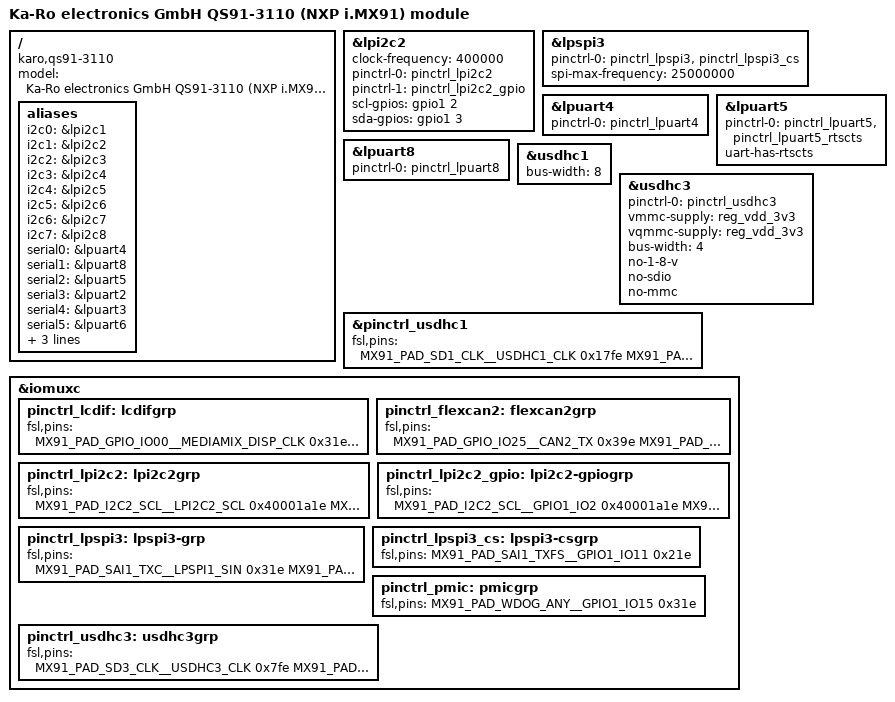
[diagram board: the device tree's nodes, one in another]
// SPDX-License-Identifier: (GPL-2.0+ OR MIT)
/*
 * Copyright 2025 Lothar Waßmann <LW@KARO-electronics.de>
 */

/dts-v1/;

#include "imx91-karo.dtsi"

/ {
	model = "Ka-Ro electronics GmbH QS91-3110 (NXP i.MX91) module";
	compatible = "karo,qs91-3110", "fsl,imx91";

	aliases {
		i2c0 = &lpi2c1; /* PMIC */
		i2c1 = &lpi2c2;
		i2c2 = &lpi2c3;
		i2c3 = &lpi2c4;
		i2c4 = &lpi2c5;
		i2c5 = &lpi2c6;
		i2c6 = &lpi2c7;
		i2c7 = &lpi2c8;
		serial0 = &lpuart4;
		serial1 = &lpuart8;
		serial2 = &lpuart5;
		serial3 = &lpuart2;
		serial4 = &lpuart3;
		serial5 = &lpuart6;
		serial6 = &lpuart7;
		serial7 = &lpuart1;
		mmc1 = &usdhc3;
	};
};

&lpi2c2 {
	clock-frequency = <400000>;
	pinctrl-names = "default", "gpio";
	pinctrl-0 = <&pinctrl_lpi2c2>;
	pinctrl-1 = <&pinctrl_lpi2c2_gpio>;
	scl-gpios = <&gpio1 2 (GPIO_ACTIVE_HIGH | GPIO_OPEN_DRAIN)>;
	sda-gpios = <&gpio1 3 (GPIO_ACTIVE_HIGH | GPIO_OPEN_DRAIN)>;
	status = "okay";
};

&lpspi3 {
	pinctrl-names = "default";
	pinctrl-0 = <&pinctrl_lpspi3 &pinctrl_lpspi3_cs>;
	spi-max-frequency = <25000000>;
};

&lpuart4 { /* console */
	pinctrl-names = "default";
	pinctrl-0 = <&pinctrl_lpuart4>;
	status = "okay";
};

&lpuart5 {
	pinctrl-names = "default";
	pinctrl-0 = <&pinctrl_lpuart5 &pinctrl_lpuart5_rtscts>;
	uart-has-rtscts;
	status = "okay";
};

&lpuart8 {
	pinctrl-names = "default";
	pinctrl-0 = <&pinctrl_lpuart8>;
	status = "okay";
};

&usdhc1 {
	bus-width = <8>;
};

&usdhc3 {
	pinctrl-names = "default";
	pinctrl-0 = <&pinctrl_usdhc3>;
	vmmc-supply = <&reg_vdd_3v3>;
	vqmmc-supply = <&reg_vdd_3v3>;
	bus-width = <4>;
	no-1-8-v;
	no-sdio;
	no-mmc;
	status = "okay";
};

&pinctrl_usdhc1 {
	fsl,pins = <
		MX91_PAD_SD1_CLK__USDHC1_CLK			0x17fe
		MX91_PAD_SD1_CMD__USDHC1_CMD			0x13fe
		MX91_PAD_SD1_DATA0__USDHC1_DATA0		0x13fe
		MX91_PAD_SD1_DATA1__USDHC1_DATA1		0x13fe
		MX91_PAD_SD1_DATA2__USDHC1_DATA2		0x13fe
		MX91_PAD_SD1_DATA3__USDHC1_DATA3		0x13fe
		MX91_PAD_SD1_DATA4__USDHC1_DATA4		0x13fe
		MX91_PAD_SD1_DATA5__USDHC1_DATA5		0x13fe
		MX91_PAD_SD1_DATA6__USDHC1_DATA6		0x13fe
		MX91_PAD_SD1_DATA7__USDHC1_DATA7		0x13fe
	>;
};

&iomuxc {
	pinctrl-names = "default";
	status = "okay";

	pinctrl_lcdif: lcdifgrp {
		fsl,pins = <
			MX91_PAD_GPIO_IO00__MEDIAMIX_DISP_CLK		0x31e
			MX91_PAD_GPIO_IO01__MEDIAMIX_DISP_DE		0x31e
			MX91_PAD_GPIO_IO02__MEDIAMIX_DISP_VSYNC		0x31e
			MX91_PAD_GPIO_IO03__MEDIAMIX_DISP_HSYNC		0x31e
			MX91_PAD_GPIO_IO04__MEDIAMIX_DISP_DATA0		0x31e
			MX91_PAD_GPIO_IO05__MEDIAMIX_DISP_DATA1		0x31e
			MX91_PAD_GPIO_IO06__MEDIAMIX_DISP_DATA2		0x31e
			MX91_PAD_GPIO_IO07__MEDIAMIX_DISP_DATA3		0x31e
			MX91_PAD_GPIO_IO08__MEDIAMIX_DISP_DATA4		0x31e
			MX91_PAD_GPIO_IO09__MEDIAMIX_DISP_DATA5		0x31e
			MX91_PAD_GPIO_IO10__MEDIAMIX_DISP_DATA6		0x31e
			MX91_PAD_GPIO_IO11__MEDIAMIX_DISP_DATA7		0x31e
			MX91_PAD_GPIO_IO12__MEDIAMIX_DISP_DATA8		0x31e
			MX91_PAD_GPIO_IO13__MEDIAMIX_DISP_DATA9		0x31e
			MX91_PAD_GPIO_IO14__MEDIAMIX_DISP_DATA10	0x31e
			MX91_PAD_GPIO_IO15__MEDIAMIX_DISP_DATA11	0x31e
			MX91_PAD_GPIO_IO16__MEDIAMIX_DISP_DATA12	0x31e
			MX91_PAD_GPIO_IO17__MEDIAMIX_DISP_DATA13	0x31e
			MX91_PAD_GPIO_IO18__MEDIAMIX_DISP_DATA14	0x31e
			MX91_PAD_GPIO_IO19__MEDIAMIX_DISP_DATA15	0x31e
			MX91_PAD_GPIO_IO20__MEDIAMIX_DISP_DATA16	0x31e
			MX91_PAD_GPIO_IO21__MEDIAMIX_DISP_DATA17	0x31e
			MX91_PAD_GPIO_IO22__MEDIAMIX_DISP_DATA18	0x31e
			MX91_PAD_GPIO_IO23__MEDIAMIX_DISP_DATA19	0x31e
			MX91_PAD_GPIO_IO24__MEDIAMIX_DISP_DATA20	0x31e
			MX91_PAD_GPIO_IO25__MEDIAMIX_DISP_DATA21	0x31e
			MX91_PAD_GPIO_IO26__MEDIAMIX_DISP_DATA22	0x31e
			MX91_PAD_GPIO_IO27__MEDIAMIX_DISP_DATA23	0x31e
		>;
	};

	pinctrl_flexcan2: flexcan2grp {
		fsl,pins = <
			MX91_PAD_GPIO_IO25__CAN2_TX			0x39e
			MX91_PAD_GPIO_IO27__CAN2_RX			0x39e
		>;
	};

	pinctrl_lpi2c2: lpi2c2grp {
		fsl,pins = <
			MX91_PAD_I2C2_SCL__LPI2C2_SCL			0x40001a1e
			MX91_PAD_I2C2_SDA__LPI2C2_SDA			0x40001a1e
		>;
	};

	pinctrl_lpi2c2_gpio: lpi2c2-gpiogrp {
		fsl,pins = <
			MX91_PAD_I2C2_SCL__GPIO1_IO2			0x40001a1e
			MX91_PAD_I2C2_SDA__GPIO1_IO3			0x40001a1e
		>;
	};

	pinctrl_lpspi3: lpspi3-grp {
		fsl,pins = <
			MX91_PAD_SAI1_TXC__LPSPI1_SIN			0x31e
			MX91_PAD_SAI1_RXD0__LPSPI1_SOUT			0x11e
			MX91_PAD_SAI1_TXD0__LPSPI1_SCK			0x11e
		>;
	};

	pinctrl_lpspi3_cs: lpspi3-csgrp {
		fsl,pins = <
			MX91_PAD_SAI1_TXFS__GPIO1_IO11			0x21e
		>;
	};

	pinctrl_pmic: pmicgrp {
		fsl,pins = <
			MX91_PAD_WDOG_ANY__GPIO1_IO15			0x31e
		>;
	};

	pinctrl_usdhc3: usdhc3grp {
		fsl,pins = <
			MX91_PAD_SD3_CLK__USDHC3_CLK			0x7fe
			MX91_PAD_SD3_CMD__USDHC3_CMD			0x3fe
			MX91_PAD_SD3_DATA0__USDHC3_DATA0		0x3fe
			MX91_PAD_SD3_DATA1__USDHC3_DATA1		0x3fe
			MX91_PAD_SD3_DATA2__USDHC3_DATA2		0x3fe
			MX91_PAD_SD3_DATA3__USDHC3_DATA3		0x1fe
		>;
	};
};
